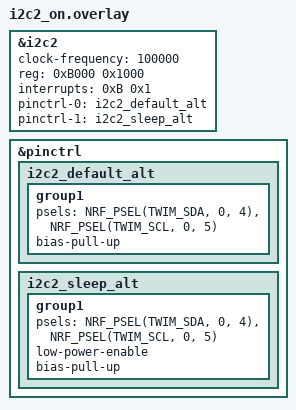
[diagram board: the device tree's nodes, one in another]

&i2c2 {
	status = "okay";
};

&pinctrl {
	i2c2_default_alt: i2c2_default_alt {
		group1 {
			psels = <NRF_PSEL(TWIM_SDA, 0, 4)>,
					<NRF_PSEL(TWIM_SCL, 0, 5)>;
			bias-pull-up;
		};
	};

	i2c2_sleep_alt: i2c2_sleep_alt {
		group1 {
			psels = <NRF_PSEL(TWIM_SDA, 0, 4)>,
					<NRF_PSEL(TWIM_SCL, 0, 5)>;
			low-power-enable;
			bias-pull-up;
		};
	};
};

&i2c2 {
	#address-cells = < 0x1 >;
	#size-cells = < 0x0 >;
	clock-frequency = < 100000 >;
	reg = < 0xB000 0x1000 >;
	interrupts = < 0xB 0x1 >;
	status = "okay";
	pinctrl-0 = <&i2c2_default_alt>;
	pinctrl-1 = <&i2c2_sleep_alt>;
	pinctrl-names = "default", "sleep";
};
